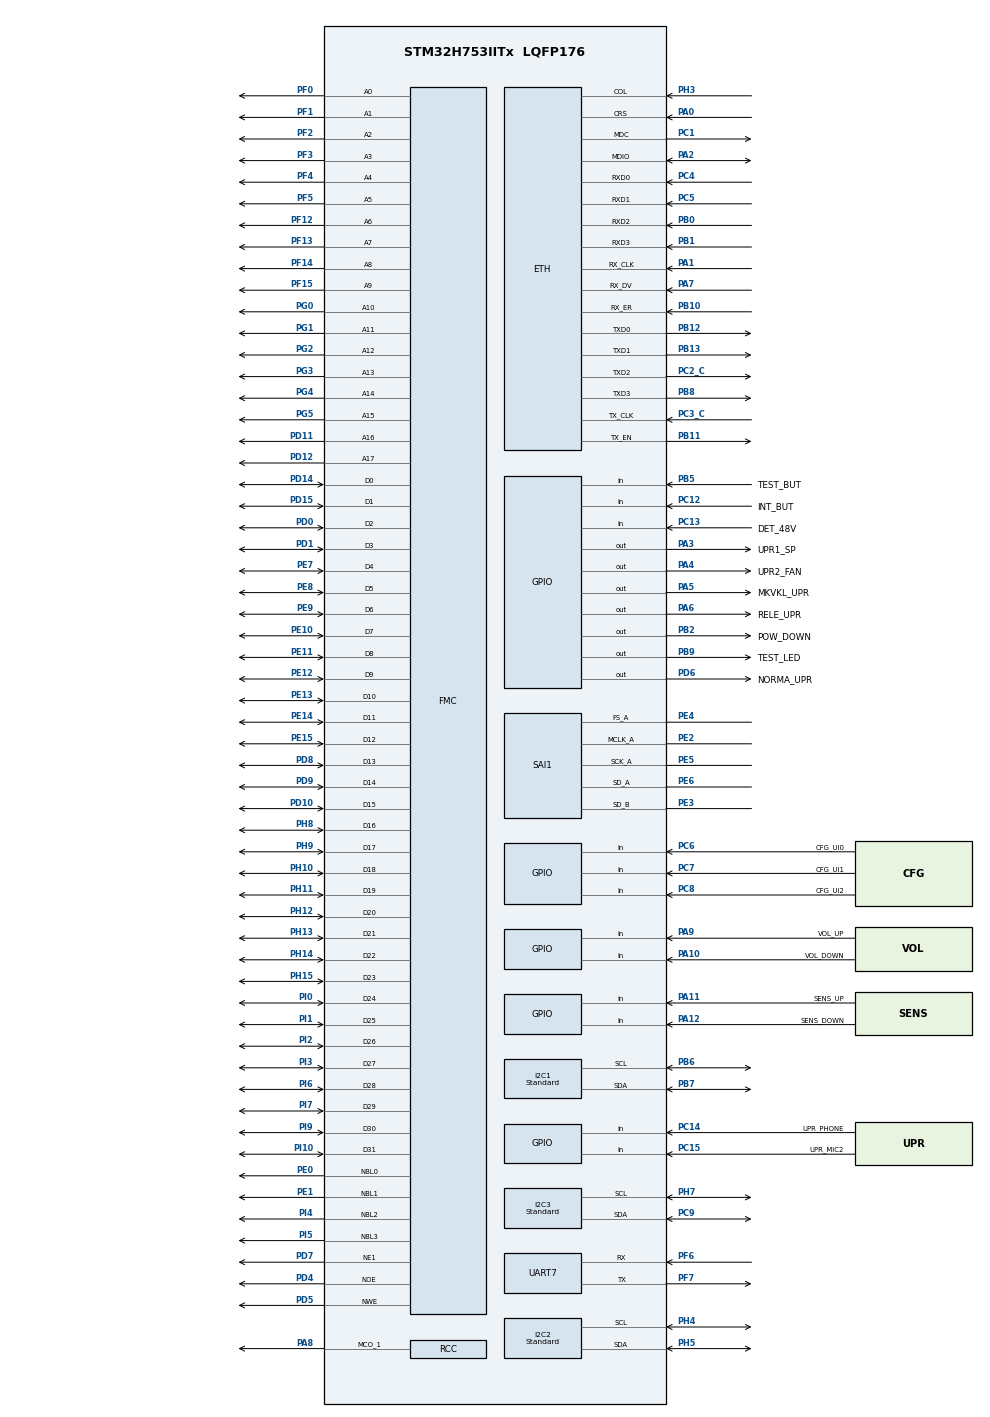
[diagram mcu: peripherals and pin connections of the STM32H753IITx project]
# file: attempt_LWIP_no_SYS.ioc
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CORTEX_M7.AccessPermission-Cortex_Memory_Protection_Unit_Region0_Settings=MPU_REGION_FULL_ACCESS
CORTEX_M7.AccessPermission-Cortex_Memory_Protection_Unit_Region1_Settings=MPU_REGION_FULL_ACCESS
CORTEX_M7.BaseAddress-Cortex_Memory_Protection_Unit_Region0_Settings=0x30000000
CORTEX_M7.BaseAddress-Cortex_Memory_Protection_Unit_Region1_Settings=0x30040000
CORTEX_M7.CPU_DCache=Disabled
CORTEX_M7.CPU_ICache=Disabled
CORTEX_M7.DisableExec-Cortex_Memory_Protection_Unit_Region0_Settings=MPU_INSTRUCTION_ACCESS_ENABLE
CORTEX_M7.Enable-Cortex_Memory_Protection_Unit_Region0_Settings=MPU_REGION_ENABLE
CORTEX_M7.Enable-Cortex_Memory_Protection_Unit_Region1_Settings=MPU_REGION_ENABLE
CORTEX_M7.IsBufferable-Cortex_Memory_Protection_Unit_Region0_Settings=MPU_ACCESS_NOT_BUFFERABLE
CORTEX_M7.IsShareable-Cortex_Memory_Protection_Unit_Region0_Settings=MPU_ACCESS_SHAREABLE
CORTEX_M7.IsShareable-Cortex_Memory_Protection_Unit_Region1_Settings=MPU_ACCESS_SHAREABLE
CORTEX_M7.MPU_Control=__NULL
CORTEX_M7.Size-Cortex_Memory_Protection_Unit_Region0_Settings=MPU_REGION_SIZE_512B
CORTEX_M7.Size-Cortex_Memory_Protection_Unit_Region1_Settings=MPU_REGION_SIZE_32KB
CORTEX_M7.TypeExtField-Cortex_Memory_Protection_Unit_Region0_Settings=MPU_TEX_LEVEL1
CORTEX_M7.TypeExtField-Cortex_Memory_Protection_Unit_Region1_Settings=MPU_TEX_LEVEL0
Dma.Request0=SAI1_A
Dma.Request1=SAI1_B
Dma.SAI1_A.0.Direction=DMA_MEMORY_TO_PERIPH
Dma.SAI1_A.0.EventEnable=DISABLE
Dma.SAI1_A.0.FIFOMode=DMA_FIFOMODE_ENABLE
Dma.SAI1_A.0.FIFOThreshold=DMA_FIFO_THRESHOLD_FULL
Dma.SAI1_A.0.Instance=DMA1_Stream0
Dma.SAI1_A.0.MemBurst=DMA_MBURST_INC8
Dma.SAI1_A.0.MemDataAlignment=DMA_MDATAALIGN_HALFWORD
Dma.SAI1_A.0.MemInc=DMA_MINC_ENABLE
Dma.SAI1_A.0.Mode=DMA_CIRCULAR
Dma.SAI1_A.0.PeriphBurst=DMA_PBURST_SINGLE
Dma.SAI1_A.0.PeriphDataAlignment=DMA_PDATAALIGN_HALFWORD
Dma.SAI1_A.0.PeriphInc=DMA_PINC_DISABLE
Dma.SAI1_A.0.Polarity=HAL_DMAMUX_REQ_GEN_RISING
Dma.SAI1_A.0.Priority=DMA_PRIORITY_VERY_HIGH
Dma.SAI1_A.0.RequestNumber=1
Dma.SAI1_A.0.SignalID=NONE
Dma.SAI1_A.0.SyncEnable=DISABLE
Dma.SAI1_A.0.SyncPolarity=HAL_DMAMUX_SYNC_NO_EVENT
Dma.SAI1_A.0.SyncRequestNumber=1
Dma.SAI1_A.0.SyncSignalID=NONE
Dma.SAI1_B.1.Direction=DMA_PERIPH_TO_MEMORY
Dma.SAI1_B.1.EventEnable=DISABLE
Dma.SAI1_B.1.FIFOMode=DMA_FIFOMODE_ENABLE
Dma.SAI1_B.1.FIFOThreshold=DMA_FIFO_THRESHOLD_FULL
Dma.SAI1_B.1.Instance=DMA1_Stream1
Dma.SAI1_B.1.MemBurst=DMA_MBURST_INC8
Dma.SAI1_B.1.MemDataAlignment=DMA_MDATAALIGN_HALFWORD
Dma.SAI1_B.1.MemInc=DMA_MINC_ENABLE
Dma.SAI1_B.1.Mode=DMA_CIRCULAR
Dma.SAI1_B.1.PeriphBurst=DMA_PBURST_SINGLE
Dma.SAI1_B.1.PeriphDataAlignment=DMA_PDATAALIGN_HALFWORD
Dma.SAI1_B.1.PeriphInc=DMA_PINC_DISABLE
Dma.SAI1_B.1.Polarity=HAL_DMAMUX_REQ_GEN_RISING
Dma.SAI1_B.1.Priority=DMA_PRIORITY_VERY_HIGH
Dma.SAI1_B.1.RequestNumber=1
Dma.SAI1_B.1.SignalID=NONE
Dma.SAI1_B.1.SyncEnable=DISABLE
Dma.SAI1_B.1.SyncPolarity=HAL_DMAMUX_SYNC_NO_EVENT
Dma.SAI1_B.1.SyncRequestNumber=1
Dma.SAI1_B.1.SyncSignalID=NONE
ETH.MACAddr=30\:31\:32\:00\:00\:00
ETH.MediaInterface=HAL_ETH_MII_MODE
ETH.RxBuffAddress=0x30000100
ETH.RxBuffLen=1524
ETH.RxDescAddress=0x30000000
ETH.TxDescAddress=0x30000080
FMC.WriteOperation1=FMC_WRITE_OPERATION_ENABLE
I2C1.I2C_Speed_Mode=I2C_Standard
I2C1.Timing=0x307075B1
I2C2.I2C_Speed_Mode=I2C_Standard
I2C2.Timing=0x307075B1
I2C3.CustomTiming=Disabled
I2C3.I2C_Fall_Time=0
I2C3.I2C_Rise_Time=0
I2C3.I2C_Speed_Mode=I2C_Standard
I2C3.Speed=100
I2C3.Timing=0x307075B1
Mcu.Family=STM32H7
Mcu.Name=STM32H753IITx
Mcu.Package=LQFP176
NVIC.DMA1_Stream0_IRQn=true\:0\:0\:false\:false\:true\:false\:true
NVIC.DMA1_Stream1_IRQn=true\:0\:0\:false\:false\:true\:false\:true
NVIC.ETH_IRQn=true\:1\:0\:true\:false\:true\:true\:true
NVIC.ETH_WKUP_IRQn=true\:1\:0\:true\:false\:true\:true\:true
NVIC.I2C3_EV_IRQn=true\:1\:0\:true\:false\:true\:true\:true
NVIC.PriorityGroup=NVIC_PRIORITYGROUP_4
NVIC.SAI1_IRQn=true\:2\:0\:true\:false\:true\:true\:true
NVIC.TIM3_IRQn=true\:5\:0\:true\:false\:true\:true\:true
NVIC.UART7_IRQn=true\:8\:0\:true\:false\:true\:true\:true
PA0.Mode=MII
PA0.PinAttribute=Free
PA0.Signal=ETH_CRS
PA1.Mode=MII
PA1.PinAttribute=Free
PA1.Signal=ETH_RX_CLK
PA10.GPIO_Label=VOL_DOWN
PA10.GPIO_PuPd=GPIO_PULLUP
PA10.PinAttribute=Free
PA10.Signal=GPIO_Input
PA11.GPIO_Label=SENS_UP
PA11.GPIO_PuPd=GPIO_PULLUP
PA11.PinAttribute=Free
PA11.Signal=GPIO_Input
PA12.GPIO_Label=SENS_DOWN
PA12.GPIO_PuPd=GPIO_PULLUP
PA12.PinAttribute=Free
PA12.Signal=GPIO_Input
PA13\ (JTMS/SWDIO).Mode=JTAG_5_pins
PA13\ (JTMS/SWDIO).PinAttribute=Free
PA13\ (JTMS/SWDIO).Signal=DEBUG_JTMS-SWDIO
PA14\ (JTCK/SWCLK).Mode=JTAG_5_pins
PA14\ (JTCK/SWCLK).PinAttribute=Free
PA14\ (JTCK/SWCLK).Signal=DEBUG_JTCK-SWCLK
PA15\ (JTDI).Mode=JTAG_5_pins
PA15\ (JTDI).PinAttribute=Free
PA15\ (JTDI).Signal=DEBUG_JTDI
PA2.Mode=MII
PA2.PinAttribute=Free
PA2.Signal=ETH_MDIO
PA3.GPIO_Label=UPR1_SP
PA3.GPIO_PuPd=GPIO_PULLUP
PA3.PinAttribute=Free
PA3.PinState=GPIO_PIN_RESET
PA3.Signal=GPIO_Output
PA4.GPIO_Label=UPR2_FAN
PA4.GPIO_PuPd=GPIO_PULLUP
PA4.PinAttribute=Free
PA4.PinState=GPIO_PIN_SET
PA4.Signal=GPIO_Output
PA5.GPIO_Label=MKVKL_UPR
PA5.GPIO_PuPd=GPIO_PULLUP
PA5.PinAttribute=Free
PA5.Signal=GPIO_Output
PA6.GPIO_Label=RELE_UPR
PA6.GPIO_PuPd=GPIO_PULLUP
PA6.PinAttribute=Free
PA6.PinState=GPIO_PIN_SET
PA6.Signal=GPIO_Output
PA7.Mode=MII
PA7.PinAttribute=Free
PA7.Signal=ETH_RX_DV
PA8.GPIO_PuPd=GPIO_PULLUP
PA8.Mode=Clock-out-1
PA8.PinAttribute=Free
PA8.Signal=RCC_MCO_1
PA9.GPIO_Label=VOL_UP
PA9.GPIO_PuPd=GPIO_PULLUP
PA9.PinAttribute=Free
PA9.Signal=GPIO_Input
PB0.Mode=MII
PB0.PinAttribute=Free
PB0.Signal=ETH_RXD2
PB1.Mode=MII
PB1.PinAttribute=Free
PB1.Signal=ETH_RXD3
PB10.Mode=Activate Rx Err signal
PB10.Signal=ETH_RX_ER
PB11.Mode=MII
PB11.PinAttribute=Free
PB11.Signal=ETH_TX_EN
PB12.Mode=MII
PB12.PinAttribute=Free
PB12.Signal=ETH_TXD0
PB13.Mode=MII
PB13.PinAttribute=Free
PB13.Signal=ETH_TXD1
PB2.GPIO_Label=POW_DOWN
PB2.GPIO_PuPd=GPIO_PULLUP
PB2.PinAttribute=Free
PB2.PinState=GPIO_PIN_SET
PB2.Signal=GPIO_Output
PB3\ (JTDO/TRACESWO).Mode=JTAG_5_pins
PB3\ (JTDO/TRACESWO).Signal=DEBUG_JTDO-SWO
PB4\ (NJTRST).Mode=JTAG_5_pins
PB4\ (NJTRST).Signal=DEBUG_JTRST
PB5.GPIO_Label=TEST_BUT
PB5.GPIO_PuPd=GPIO_PULLUP
PB5.Signal=GPIO_Input
PB6.GPIO_Pu=GPIO_PULLUP
PB6.GPIO_PuPd=GPIO_PULLUP
PB6.GPIO_Speed=GPIO_SPEED_FREQ_HIGH
PB6.Mode=I2C
PB6.PinAttribute=Free
PB6.Signal=I2C1_SCL
PB7.GPIO_Pu=GPIO_PULLUP
PB7.GPIO_PuPd=GPIO_PULLUP
PB7.GPIO_Speed=GPIO_SPEED_FREQ_HIGH
PB7.Mode=I2C
PB7.PinAttribute=Free
PB7.Signal=I2C1_SDA
PB8.GPIO_FM8=__NULL
PB8.Mode=MII
PB8.PinAttribute=Free
PB8.Signal=ETH_TXD3
PB9.GPIO_Label=TEST_LED
PB9.GPIO_ModeDefaultOutputPP=GPIO_MODE_OUTPUT_PP
PB9.GPIO_PuPd=GPIO_PULLUP
PB9.Signal=GPIO_Output
PC1.Mode=MII
PC1.PinAttribute=Free
PC1.Signal=ETH_MDC
PC12.GPIO_Label=INT_BUT
PC12.GPIO_PuPd=GPIO_PULLUP
PC12.PinAttribute=Free
PC12.Signal=GPIO_Input
PC13.GPIO_Label=DET_48V
PC13.GPIO_PuPd=GPIO_PULLUP
PC13.PinAttribute=Free
PC13.Signal=GPIO_Input
PC14-OSC32_IN\ (OSC32_IN).GPIO_Label=UPR_PHONE
PC14-OSC32_IN\ (OSC32_IN).GPIO_PuPd=GPIO_PULLUP
PC14-OSC32_IN\ (OSC32_IN).PinAttribute=Free
PC14-OSC32_IN\ (OSC32_IN).Signal=GPIO_Input
PC15-OSC32_OUT\ (OSC32_OUT).GPIO_Label=UPR_MIC2
PC15-OSC32_OUT\ (OSC32_OUT).GPIO_PuPd=GPIO_PULLUP
PC15-OSC32_OUT\ (OSC32_OUT).PinAttribute=Free
PC15-OSC32_OUT\ (OSC32_OUT).Signal=GPIO_Input
PC2_C.Mode=MII
PC2_C.PinAttribute=Free
PC2_C.Signal=ETH_TXD2
PC3_C.Mode=MII
PC3_C.PinAttribute=Free
PC3_C.Signal=ETH_TX_CLK
PC4.Mode=MII
PC4.PinAttribute=Free
PC4.Signal=ETH_RXD0
PC5.Mode=MII
PC5.PinAttribute=Free
PC5.Signal=ETH_RXD1
PC6.GPIO_Label=CFG_UI0
PC6.GPIO_PuPd=GPIO_PULLUP
PC6.PinAttribute=Free
PC6.Signal=GPIO_Input
PC7.GPIO_Label=CFG_UI1
PC7.GPIO_PuPd=GPIO_PULLUP
PC7.PinAttribute=Free
PC7.Signal=GPIO_Input
PC8.GPIO_Label=CFG_UI2
PC8.GPIO_PuPd=GPIO_PULLUP
PC8.PinAttribute=Free
PC8.Signal=GPIO_Input
PC9.GPIO_Mode=GPIO_MODE_AF_OD
PC9.GPIO_Pu=GPIO_PULLUP
PC9.GPIO_PuPd=GPIO_NOPULL
PC9.GPIO_Speed=GPIO_SPEED_FREQ_VERY_HIGH
PC9.Mode=I2C
PC9.PinAttribute=Free
PC9.Signal=I2C3_SDA
PD0.PinAttribute=Free
PD0.Signal=FMC_D2_DA2
PD1.PinAttribute=Free
PD1.Signal=FMC_D3_DA3
PD10.PinAttribute=Free
PD10.Signal=FMC_D15_DA15
PD11.PinAttribute=Free
PD11.Signal=FMC_A16_CLE
PD12.PinAttribute=Free
PD12.Signal=FMC_A17_ALE
PD14.PinAttribute=Free
PD14.Signal=FMC_D0_DA0
PD15.PinAttribute=Free
PD15.Signal=FMC_D1_DA1
PD4.PinAttribute=Free
PD4.Signal=FMC_NOE
PD5.PinAttribute=Free
PD5.Signal=FMC_NWE
PD6.GPIO_Label=NORMA_UPR
PD6.GPIO_PuPd=GPIO_PULLUP
PD6.PinAttribute=Free
PD6.Signal=GPIO_Output
PD7.Mode=NorPsramChipSelect1_1
PD7.Signal=FMC_NE1
PD8.PinAttribute=Free
PD8.Signal=FMC_D13_DA13
PD9.PinAttribute=Free
PD9.Signal=FMC_D14_DA14
PE0.Signal=FMC_NBL0
PE1.Signal=FMC_NBL1
PE10.PinAttribute=Free
PE10.Signal=FMC_D7_DA7
PE11.PinAttribute=Free
PE11.Signal=FMC_D8_DA8
PE12.PinAttribute=Free
PE12.Signal=FMC_D9_DA9
PE13.PinAttribute=Free
PE13.Signal=FMC_D10_DA10
PE14.PinAttribute=Free
PE14.Signal=FMC_D11_DA11
PE15.PinAttribute=Free
PE15.Signal=FMC_D12_DA12
PE2.GPIO_Speed=GPIO_SPEED_FREQ_VERY_HIGH
PE2.Mode=SAI_A_MasterWithClock
PE2.PinAttribute=Free
PE2.Signal=SAI1_MCLK_A
PE3.GPIO_Speed=GPIO_SPEED_FREQ_VERY_HIGH
PE3.Mode=SAI_B_SyncSlave
PE3.PinAttribute=Free
PE3.Signal=SAI1_SD_B
PE4.GPIO_Speed=GPIO_SPEED_FREQ_VERY_HIGH
PE4.Mode=SAI_A_MasterWithClock
PE4.PinAttribute=Free
PE4.Signal=SAI1_FS_A
PE5.GPIO_Speed=GPIO_SPEED_FREQ_VERY_HIGH
PE5.Mode=SAI_A_MasterWithClock
PE5.PinAttribute=Free
PE5.Signal=SAI1_SCK_A
PE6.GPIO_Speed=GPIO_SPEED_FREQ_VERY_HIGH
PE6.Mode=SAI_A_MasterWithClock
PE6.PinAttribute=Free
PE6.Signal=SAI1_SD_A
PE7.PinAttribute=Free
PE7.Signal=FMC_D4_DA4
PE8.PinAttribute=Free
PE8.Signal=FMC_D5_DA5
PE9.PinAttribute=Free
PE9.Signal=FMC_D6_DA6
PF0.PinAttribute=Free
PF0.Signal=FMC_A0
PF1.PinAttribute=Free
PF1.Signal=FMC_A1
PF12.PinAttribute=Free
PF12.Signal=FMC_A6
PF13.PinAttribute=Free
PF13.Signal=FMC_A7
PF14.PinAttribute=Free
PF14.Signal=FMC_A8
PF15.PinAttribute=Free
PF15.Signal=FMC_A9
PF2.PinAttribute=Free
PF2.Signal=FMC_A2
PF3.PinAttribute=Free
PF3.Signal=FMC_A3
PF4.PinAttribute=Free
PF4.Signal=FMC_A4
PF5.PinAttribute=Free
PF5.Signal=FMC_A5
PF6.GPIO_PuPd=GPIO_PULLUP
PF6.Mode=Asynchronous
PF6.PinAttribute=Free
PF6.Signal=UART7_RX
PF7.GPIO_PuPd=GPIO_PULLUP
PF7.Mode=Asynchronous
PF7.PinAttribute=Free
PF7.Signal=UART7_TX
PG0.PinAttribute=Free
PG0.Signal=FMC_A10
PG1.PinAttribute=Free
PG1.Signal=FMC_A11
PG2.PinAttribute=Free
PG2.Signal=FMC_A12
PG3.PinAttribute=Free
PG3.Signal=FMC_A13
PG4.PinAttribute=Free
PG4.Signal=FMC_A14_BA0
PG5.PinAttribute=Free
PG5.Signal=FMC_A15_BA1
PH0-OSC_IN\ (PH0).Mode=HSE-External-Oscillator
PH0-OSC_IN\ (PH0).PinAttribute=Free
PH0-OSC_IN\ (PH0).Signal=RCC_OSC_IN
PH1-OSC_OUT\ (PH1).Mode=HSE-External-Oscillator
PH1-OSC_OUT\ (PH1).PinAttribute=Free
PH1-OSC_OUT\ (PH1).Signal=RCC_OSC_OUT
PH10.PinAttribute=Free
PH10.Signal=FMC_D18
PH11.PinAttribute=Free
PH11.Signal=FMC_D19
PH12.PinAttribute=Free
PH12.Signal=FMC_D20
PH13.PinAttribute=Free
PH13.Signal=FMC_D21
PH14.PinAttribute=Free
PH14.Signal=FMC_D22
PH15.PinAttribute=Free
PH15.Signal=FMC_D23
PH3.Mode=MII
PH3.PinAttribute=Free
PH3.Signal=ETH_COL
PH4.GPIO_Pu=GPIO_PULLUP
PH4.GPIO_PuPd=GPIO_PULLUP
PH4.GPIO_Speed=GPIO_SPEED_FREQ_HIGH
PH4.Mode=I2C
PH4.PinAttribute=Free
PH4.Signal=I2C2_SCL
PH5.GPIO_Pu=GPIO_PULLUP
PH5.GPIO_PuPd=GPIO_PULLUP
PH5.GPIO_Speed=GPIO_SPEED_FREQ_HIGH
PH5.Mode=I2C
PH5.PinAttribute=Free
PH5.Signal=I2C2_SDA
PH7.GPIO_Pu=GPIO_PULLUP
PH7.GPIO_PuPd=GPIO_NOPULL
PH7.GPIO_Speed=GPIO_SPEED_FREQ_VERY_HIGH
PH7.Mode=I2C
PH7.PinAttribute=Free
PH7.Signal=I2C3_SCL
PH8.PinAttribute=Free
PH8.Signal=FMC_D16
PH9.PinAttribute=Free
PH9.Signal=FMC_D17
PI0.PinAttribute=Free
PI0.Signal=FMC_D24
PI1.PinAttribute=Free
PI1.Signal=FMC_D25
PI10.PinAttribute=Free
PI10.Signal=FMC_D31
PI2.PinAttribute=Free
PI2.Signal=FMC_D26
PI3.PinAttribute=Free
PI3.Signal=FMC_D27
PI4.Signal=FMC_NBL2
PI5.Signal=FMC_NBL3
PI6.Signal=FMC_D28
PI7.Signal=FMC_D29
PI9.PinAttribute=Free
PI9.Signal=FMC_D30
ProjectManager.HeapSize=0x200
ProjectManager.StackSize=0x400
ProjectManager.TargetToolchain=STM32CubeIDE
RCC.ADCFreq_Value=4096000
RCC.APB1Freq_Value=120000000
RCC.APB2Freq_Value=120000000
RCC.APB3Freq_Value=120000000
RCC.APB4Freq_Value=120000000
RCC.CKPERSourceSelection=RCC_CLKPSOURCE_HSE
RCC.CortexFreq_Value=480000000
RCC.D1PPRE=RCC_APB3_DIV2
RCC.D2PPRE1=RCC_APB1_DIV2
RCC.D2PPRE2=RCC_APB2_DIV2
RCC.D3PPRE=RCC_APB4_DIV2
RCC.DIVM1=10
RCC.DIVM2=25
RCC.DIVM3=25
RCC.DIVN1=384
RCC.DIVN2=512
RCC.DIVN3=150
RCC.DIVP2=125
RCC.DIVP3=1
RCC.DIVQ1=10
RCC.DIVQ2=125
RCC.DIVQ3=1
RCC.DIVR1=4
RCC.DIVR2=125
RCC.DIVR3=1
RCC.EnbaleCSS=true
RCC.FMCCLockSelection=RCC_FMCCLKSOURCE_PLL
RCC.HCLKFreq_Value=240000000
RCC.HPRE=RCC_HCLK_DIV2
RCC.HSIDiv=RCC_PLLSAIDIVR_8
RCC.PLL2FRACN=0
RCC.PLL3FRACN=0
RCC.PLLFRACN=0
RCC.PLLSourceVirtual=RCC_PLLSOURCE_HSE
RCC.RCC_MCO1Source=RCC_MCO1SOURCE_HSE
RCC.SAI1CLockSelection=RCC_SAI1CLKSOURCE_PLL2
RCC.SYSCLKFreq_VALUE=480000000
RCC.SYSCLKSource=RCC_SYSCLKSOURCE_PLLCLK
RCC.USBFreq_Value=96000000
SAI1.AudioFrequency-SAI_A_MasterWithClock=SAI_AUDIO_FREQUENCY_8K
SAI1.ErrorAudioFreq-SAI_A_MasterWithClock=0.0 %
SAI1.InitProtocol-SAI_A_MasterWithClock=Enable
SAI1.InitProtocol-SAI_B_SyncSlave=Enable
SAI1.Instance-SAI_A_MasterWithClock=SAI$Index_Block_A
SAI1.Instance-SAI_B_SyncSlave=SAI$Index_Block_B
SAI1.MClockEnable-SAI_A_MasterWithClock=SAI_MASTERCLOCK_ENABLE
SAI1.MonoStereoMode-SAI_A_MasterWithClock=SAI_STEREOMODE
SAI1.MonoStereoMode-SAI_B_SyncSlave=SAI_STEREOMODE
SAI1.RealAudioFreq-SAI_A_MasterWithClock=8.0 KHz
SAI1.VirtualMode-SAI_A_MasterWithClock=VM_MASTER
SAI1.VirtualMode-SAI_B_SyncSlave=VM_SLAVE
SAI1.VirtualProtocol-SAI_A_BASIC=VM_BASIC_PROTOCOL
SAI1.VirtualProtocol-SAI_B_BASIC=VM_BASIC_PROTOCOL
SH.FMC_A0.0=FMC_A0,18b-a1
SH.FMC_A1.0=FMC_A1,18b-a1
SH.FMC_A10.0=FMC_A10,18b-a1
SH.FMC_A11.0=FMC_A11,18b-a1
SH.FMC_A12.0=FMC_A12,18b-a1
SH.FMC_A13.0=FMC_A13,18b-a1
SH.FMC_A14_BA0.0=FMC_A14,18b-a1
SH.FMC_A15_BA1.0=FMC_A15,18b-a1
SH.FMC_A16_CLE.0=FMC_A16,18b-a1
SH.FMC_A17_ALE.0=FMC_A17,18b-a1
SH.FMC_A2.0=FMC_A2,18b-a1
SH.FMC_A3.0=FMC_A3,18b-a1
SH.FMC_A4.0=FMC_A4,18b-a1
SH.FMC_A5.0=FMC_A5,18b-a1
SH.FMC_A6.0=FMC_A6,18b-a1
SH.FMC_A7.0=FMC_A7,18b-a1
SH.FMC_A8.0=FMC_A8,18b-a1
SH.FMC_A9.0=FMC_A9,18b-a1
SH.FMC_D0_DA0.0=FMC_D0,32b-d1
SH.FMC_D10_DA10.0=FMC_D10,32b-d1
SH.FMC_D11_DA11.0=FMC_D11,32b-d1
SH.FMC_D12_DA12.0=FMC_D12,32b-d1
SH.FMC_D13_DA13.0=FMC_D13,32b-d1
SH.FMC_D14_DA14.0=FMC_D14,32b-d1
SH.FMC_D15_DA15.0=FMC_D15,32b-d1
SH.FMC_D16.0=FMC_D16,32b-d1
SH.FMC_D17.0=FMC_D17,32b-d1
SH.FMC_D18.0=FMC_D18,32b-d1
SH.FMC_D19.0=FMC_D19,32b-d1
SH.FMC_D1_DA1.0=FMC_D1,32b-d1
SH.FMC_D20.0=FMC_D20,32b-d1
SH.FMC_D21.0=FMC_D21,32b-d1
SH.FMC_D22.0=FMC_D22,32b-d1
SH.FMC_D23.0=FMC_D23,32b-d1
SH.FMC_D24.0=FMC_D24,32b-d1
SH.FMC_D25.0=FMC_D25,32b-d1
SH.FMC_D26.0=FMC_D26,32b-d1
SH.FMC_D27.0=FMC_D27,32b-d1
SH.FMC_D28.0=FMC_D28,32b-d1
SH.FMC_D29.0=FMC_D29,32b-d1
SH.FMC_D2_DA2.0=FMC_D2,32b-d1
SH.FMC_D30.0=FMC_D30,32b-d1
SH.FMC_D31.0=FMC_D31,32b-d1
SH.FMC_D3_DA3.0=FMC_D3,32b-d1
SH.FMC_D4_DA4.0=FMC_D4,32b-d1
SH.FMC_D5_DA5.0=FMC_D5,32b-d1
SH.FMC_D6_DA6.0=FMC_D6,32b-d1
SH.FMC_D7_DA7.0=FMC_D7,32b-d1
SH.FMC_D8_DA8.0=FMC_D8,32b-d1
SH.FMC_D9_DA9.0=FMC_D9,32b-d1
SH.FMC_NBL0.0=FMC_NBL0,4ByteEnable1
SH.FMC_NBL1.0=FMC_NBL1,4ByteEnable1
SH.FMC_NBL2.0=FMC_NBL2,4ByteEnable1
SH.FMC_NBL3.0=FMC_NBL3,4ByteEnable1
SH.FMC_NOE.0=FMC_NOE,Sram1
SH.FMC_NWE.0=FMC_NWE,Sram1
TIM3.Period=15000
UART7.FIFOMode=FIFOMODE_ENABLE
UART7.RXFIFOThreshold=RXFIFO_THRESHOLD_HALFFULL
UART7.TXFIFOThreshold=TXFIFO_THRESHOLD_HALFFULL
VP_SAI1_VP_$IpInstance_SAIA_SAI_BASIC.Mode=SAI_A_BASIC
VP_SAI1_VP_$IpInstance_SAIB_SAI_BASIC.Mode=SAI_B_BASIC
VP_TIM3_VS_ClockSourceINT.Mode=Internal
board=custom

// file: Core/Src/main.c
/* USER CODE BEGIN Header */
/**
  ******************************************************************************
  * @file           : main.c
  * @brief          : Main program body
  ******************************************************************************
  * @attention
  *
  * Copyright (c) 2022 STMicroelectronics.
  * All rights reserved.
  *
  * This software is licensed under terms that can be found in the LICENSE file
  * in the root directory of this software component.
  * If no LICENSE file comes with this software, it is provided AS-IS.
  *
  ******************************************************************************
  */
/* USER CODE END Header */
#include "main.h"
#include "string.h"

#if defined ( __ICCARM__ ) /*!< IAR Compiler */

#pragma location=0x30000000
ETH_DMADescTypeDef  DMARxDscrTab[ETH_RX_DESC_CNT]; /* Ethernet Rx DMA Descriptors */
#pragma location=0x30000080
ETH_DMADescTypeDef  DMATxDscrTab[ETH_TX_DESC_CNT]; /* Ethernet Tx DMA Descriptors */
#pragma location=0x30000100
uint8_t Rx_Buff[ETH_RX_DESC_CNT][ETH_MAX_PACKET_SIZE]; /* Ethernet Receive Buffers */

#elif defined ( __CC_ARM )  /* MDK ARM Compiler */

__attribute__((at(0x30000000))) ETH_DMADescTypeDef  DMARxDscrTab[ETH_RX_DESC_CNT]; /* Ethernet Rx DMA Descriptors */
__attribute__((at(0x30000080))) ETH_DMADescTypeDef  DMATxDscrTab[ETH_TX_DESC_CNT]; /* Ethernet Tx DMA Descriptors */
__attribute__((at(0x30000100))) uint8_t Rx_Buff[ETH_RX_DESC_CNT][ETH_MAX_PACKET_SIZE]; /* Ethernet Receive Buffer */

#elif defined ( __GNUC__ ) /* GNU Compiler */

ETH_DMADescTypeDef DMARxDscrTab[ETH_RX_DESC_CNT] __attribute__((section(".RxDecripSection"))); /* Ethernet Rx DMA Descriptors */
ETH_DMADescTypeDef DMATxDscrTab[ETH_TX_DESC_CNT] __attribute__((section(".TxDecripSection")));   /* Ethernet Tx DMA Descriptors */
uint8_t Rx_Buff[ETH_RX_DESC_CNT][ETH_MAX_PACKET_SIZE] __attribute__((section(".RxArraySection"))); /* Ethernet Receive Buffers */

#endif

ETH_TxPacketConfig TxConfig;

ETH_HandleTypeDef heth;

I2C_HandleTypeDef hi2c1;
I2C_HandleTypeDef hi2c2;
I2C_HandleTypeDef hi2c3;

SAI_HandleTypeDef hsai_BlockA1;
SAI_HandleTypeDef hsai_BlockB1;
DMA_HandleTypeDef hdma_sai1_a;
DMA_HandleTypeDef hdma_sai1_b;

TIM_HandleTypeDef htim3;

UART_HandleTypeDef huart7;

SRAM_HandleTypeDef hsram1;

void SystemClock_Config(void);
void PeriphCommonClock_Config(void);
static void MX_GPIO_Init(void);
static void MX_DMA_Init(void);
static void MX_FMC_Init(void);
static void MX_I2C1_Init(void);
static void MX_I2C2_Init(void);
static void MX_I2C3_Init(void);
static void MX_SAI1_Init(void);
static void MX_UART7_Init(void);
static void MX_TIM3_Init(void);
static void MX_ETH_Init(void);
/* USER CODE BEGIN PFP */
extern struct netif gnetif;
/* USER CODE END PFP */

int main(void)
{

  /* MCU Configuration--------------------------------------------------------*/

  /* Reset of all peripherals, Initializes the Flash interface and the Systick. */
  HAL_Init();

  /* Configure the system clock */
  SystemClock_Config();

/* Configure the peripherals common clocks */
  PeriphCommonClock_Config();

  /* Initialize all configured peripherals */
  MX_GPIO_Init();
  MX_DMA_Init();
  MX_FMC_Init();
  MX_I2C1_Init();
  MX_I2C2_Init();
  MX_I2C3_Init();
  MX_SAI1_Init();
  MX_UART7_Init();
  MX_TIM3_Init();
  MX_ETH_Init();

  /* Infinite loop */
  while (1)
  {

  }
}

void SystemClock_Config(void)
{
  RCC_OscInitTypeDef RCC_OscInitStruct = {0};
  RCC_ClkInitTypeDef RCC_ClkInitStruct = {0};

  /** Supply configuration update enable
  */
  HAL_PWREx_ConfigSupply(PWR_LDO_SUPPLY);
  /** Configure the main internal regulator output voltage
  */
  __HAL_PWR_VOLTAGESCALING_CONFIG(PWR_REGULATOR_VOLTAGE_SCALE0);

  while(!__HAL_PWR_GET_FLAG(PWR_FLAG_VOSRDY)) {}
  /** Macro to configure the PLL clock source
  */
  __HAL_RCC_PLL_PLLSOURCE_CONFIG(RCC_PLLSOURCE_HSE);
  /** Initializes the RCC Oscillators according to the specified parameters
  * in the RCC_OscInitTypeDef structure.
  */
  RCC_OscInitStruct.OscillatorType = RCC_OSCILLATORTYPE_HSE;
  RCC_OscInitStruct.HSEState = RCC_HSE_ON;
  RCC_OscInitStruct.PLL.PLLState = RCC_PLL_ON;
  RCC_OscInitStruct.PLL.PLLSource = RCC_PLLSOURCE_HSE;
  RCC_OscInitStruct.PLL.PLLM = 10;
  RCC_OscInitStruct.PLL.PLLN = 384;
  RCC_OscInitStruct.PLL.PLLP = 2;
  RCC_OscInitStruct.PLL.PLLQ = 10;
  RCC_OscInitStruct.PLL.PLLR = 4;
  RCC_OscInitStruct.PLL.PLLRGE = RCC_PLL1VCIRANGE_1;
  RCC_OscInitStruct.PLL.PLLVCOSEL = RCC_PLL1VCOWIDE;
  RCC_OscInitStruct.PLL.PLLFRACN = 0;
  if (HAL_RCC_OscConfig(&RCC_OscInitStruct) != HAL_OK)
  {
    Error_Handler();
  }
  /** Initializes the CPU, AHB and APB buses clocks
  */
  RCC_ClkInitStruct.ClockType = RCC_CLOCKTYPE_HCLK|RCC_CLOCKTYPE_SYSCLK
                              |RCC_CLOCKTYPE_PCLK1|RCC_CLOCKTYPE_PCLK2
                              |RCC_CLOCKTYPE_D3PCLK1|RCC_CLOCKTYPE_D1PCLK1;
  RCC_ClkInitStruct.SYSCLKSource = RCC_SYSCLKSOURCE_PLLCLK;
  RCC_ClkInitStruct.SYSCLKDivider = RCC_SYSCLK_DIV1;
  RCC_ClkInitStruct.AHBCLKDivider = RCC_HCLK_DIV2;
  RCC_ClkInitStruct.APB3CLKDivider = RCC_APB3_DIV2;
  RCC_ClkInitStruct.APB1CLKDivider = RCC_APB1_DIV2;
  RCC_ClkInitStruct.APB2CLKDivider = RCC_APB2_DIV2;
  RCC_ClkInitStruct.APB4CLKDivider = RCC_APB4_DIV2;

  if (HAL_RCC_ClockConfig(&RCC_ClkInitStruct, FLASH_LATENCY_4) != HAL_OK)
  {
    Error_Handler();
  }
  HAL_RCC_MCOConfig(RCC_MCO1, RCC_MCO1SOURCE_HSE, RCC_MCODIV_1);
  /** Enables the Clock Security System
  */
  HAL_RCC_EnableCSS();
}

void PeriphCommonClock_Config(void)
{
  RCC_PeriphCLKInitTypeDef PeriphClkInitStruct = {0};

  /** Initializes the peripherals clock
  */
  PeriphClkInitStruct.PeriphClockSelection = RCC_PERIPHCLK_SAI1;
  PeriphClkInitStruct.PLL2.PLL2M = 25;
  PeriphClkInitStruct.PLL2.PLL2N = 512;
  PeriphClkInitStruct.PLL2.PLL2P = 125;
  PeriphClkInitStruct.PLL2.PLL2Q = 125;
  PeriphClkInitStruct.PLL2.PLL2R = 125;
  PeriphClkInitStruct.PLL2.PLL2RGE = RCC_PLL2VCIRANGE_0;
  PeriphClkInitStruct.PLL2.PLL2VCOSEL = RCC_PLL2VCOWIDE;
  PeriphClkInitStruct.PLL2.PLL2FRACN = 0;
  PeriphClkInitStruct.Sai1ClockSelection = RCC_SAI1CLKSOURCE_PLL2;
  if (HAL_RCCEx_PeriphCLKConfig(&PeriphClkInitStruct) != HAL_OK)
  {
    Error_Handler();
  }
}

static void MX_ETH_Init(void)
{

   static uint8_t MACAddr[6];

  heth.Instance = ETH;
  MACAddr[0] = 0x30;
  MACAddr[1] = 0x31;
  MACAddr[2] = 0x32;
  MACAddr[3] = 0x00;
  MACAddr[4] = 0x00;
  MACAddr[5] = 0x00;
  heth.Init.MACAddr = &MACAddr[0];
  heth.Init.MediaInterface = HAL_ETH_MII_MODE;
  heth.Init.TxDesc = DMATxDscrTab;
  heth.Init.RxDesc = DMARxDscrTab;
  heth.Init.RxBuffLen = 1524;

  if (HAL_ETH_Init(&heth) != HAL_OK)
  {
    Error_Handler();
  }

  memset(&TxConfig, 0 , sizeof(ETH_TxPacketConfig));
  TxConfig.Attributes = ETH_TX_PACKETS_FEATURES_CSUM | ETH_TX_PACKETS_FEATURES_CRCPAD;
  TxConfig.ChecksumCtrl = ETH_CHECKSUM_IPHDR_PAYLOAD_INSERT_PHDR_CALC;
  TxConfig.CRCPadCtrl = ETH_CRC_PAD_INSERT;

}

static void MX_I2C1_Init(void)
{

  hi2c1.Instance = I2C1;
  hi2c1.Init.Timing = 0x307075B1;
  hi2c1.Init.OwnAddress1 = 0;
  hi2c1.Init.AddressingMode = I2C_ADDRESSINGMODE_7BIT;
  hi2c1.Init.DualAddressMode = I2C_DUALADDRESS_DISABLE;
  hi2c1.Init.OwnAddress2 = 0;
  hi2c1.Init.OwnAddress2Masks = I2C_OA2_NOMASK;
  hi2c1.Init.GeneralCallMode = I2C_GENERALCALL_DISABLE;
  hi2c1.Init.NoStretchMode = I2C_NOSTRETCH_DISABLE;
  if (HAL_I2C_Init(&hi2c1) != HAL_OK)
  {
    Error_Handler();
  }
  /** Configure Analogue filter
  */
  if (HAL_I2CEx_ConfigAnalogFilter(&hi2c1, I2C_ANALOGFILTER_ENABLE) != HAL_OK)
  {
    Error_Handler();
  }
  /** Configure Digital filter
  */
  if (HAL_I2CEx_ConfigDigitalFilter(&hi2c1, 0) != HAL_OK)
  {
    Error_Handler();
  }

}

static void MX_I2C2_Init(void)
{

  hi2c2.Instance = I2C2;
  hi2c2.Init.Timing = 0x307075B1;
  hi2c2.Init.OwnAddress1 = 0;
  hi2c2.Init.AddressingMode = I2C_ADDRESSINGMODE_7BIT;
  hi2c2.Init.DualAddressMode = I2C_DUALADDRESS_DISABLE;
  hi2c2.Init.OwnAddress2 = 0;
  hi2c2.Init.OwnAddress2Masks = I2C_OA2_NOMASK;
  hi2c2.Init.GeneralCallMode = I2C_GENERALCALL_DISABLE;
  hi2c2.Init.NoStretchMode = I2C_NOSTRETCH_DISABLE;
  if (HAL_I2C_Init(&hi2c2) != HAL_OK)
  {
    Error_Handler();
  }
  /** Configure Analogue filter
  */
  if (HAL_I2CEx_ConfigAnalogFilter(&hi2c2, I2C_ANALOGFILTER_ENABLE) != HAL_OK)
  {
    Error_Handler();
  }
  /** Configure Digital filter
  */
  if (HAL_I2CEx_ConfigDigitalFilter(&hi2c2, 0) != HAL_OK)
  {
    Error_Handler();
  }

}

static void MX_I2C3_Init(void)
{

  hi2c3.Instance = I2C3;
  hi2c3.Init.Timing = 0x307075B1;
  hi2c3.Init.OwnAddress1 = 0;
  hi2c3.Init.AddressingMode = I2C_ADDRESSINGMODE_7BIT;
  hi2c3.Init.DualAddressMode = I2C_DUALADDRESS_DISABLE;
  hi2c3.Init.OwnAddress2 = 0;
  hi2c3.Init.OwnAddress2Masks = I2C_OA2_NOMASK;
  hi2c3.Init.GeneralCallMode = I2C_GENERALCALL_DISABLE;
  hi2c3.Init.NoStretchMode = I2C_NOSTRETCH_DISABLE;
  if (HAL_I2C_Init(&hi2c3) != HAL_OK)
  {
    Error_Handler();
  }
  /** Configure Analogue filter
  */
  if (HAL_I2CEx_ConfigAnalogFilter(&hi2c3, I2C_ANALOGFILTER_ENABLE) != HAL_OK)
  {
    Error_Handler();
  }
  /** Configure Digital filter
  */
  if (HAL_I2CEx_ConfigDigitalFilter(&hi2c3, 0) != HAL_OK)
  {
    Error_Handler();
  }

}

static void MX_SAI1_Init(void)
{

  hsai_BlockA1.Instance = SAI1_Block_A;
  hsai_BlockA1.Init.AudioMode = SAI_MODEMASTER_TX;
  hsai_BlockA1.Init.Synchro = SAI_ASYNCHRONOUS;
  hsai_BlockA1.Init.OutputDrive = SAI_OUTPUTDRIVE_DISABLE;
  hsai_BlockA1.Init.NoDivider = SAI_MASTERDIVIDER_ENABLE;
  hsai_BlockA1.Init.FIFOThreshold = SAI_FIFOTHRESHOLD_EMPTY;
  hsai_BlockA1.Init.AudioFrequency = SAI_AUDIO_FREQUENCY_8K;
  hsai_BlockA1.Init.SynchroExt = SAI_SYNCEXT_DISABLE;
  hsai_BlockA1.Init.MonoStereoMode = SAI_STEREOMODE;
  hsai_BlockA1.Init.CompandingMode = SAI_NOCOMPANDING;
  hsai_BlockA1.Init.TriState = SAI_OUTPUT_NOTRELEASED;
  if (HAL_SAI_InitProtocol(&hsai_BlockA1, SAI_I2S_STANDARD, SAI_PROTOCOL_DATASIZE_16BIT, 2) != HAL_OK)
  {
    Error_Handler();
  }
  hsai_BlockB1.Instance = SAI1_Block_B;
  hsai_BlockB1.Init.AudioMode = SAI_MODESLAVE_RX;
  hsai_BlockB1.Init.Synchro = SAI_SYNCHRONOUS;
  hsai_BlockB1.Init.OutputDrive = SAI_OUTPUTDRIVE_DISABLE;
  hsai_BlockB1.Init.FIFOThreshold = SAI_FIFOTHRESHOLD_EMPTY;
  hsai_BlockB1.Init.SynchroExt = SAI_SYNCEXT_DISABLE;
  hsai_BlockB1.Init.MonoStereoMode = SAI_STEREOMODE;
  hsai_BlockB1.Init.CompandingMode = SAI_NOCOMPANDING;
  hsai_BlockB1.Init.TriState = SAI_OUTPUT_NOTRELEASED;
  if (HAL_SAI_InitProtocol(&hsai_BlockB1, SAI_I2S_STANDARD, SAI_PROTOCOL_DATASIZE_16BIT, 2) != HAL_OK)
  {
    Error_Handler();
  }

}

static void MX_TIM3_Init(void)
{

  TIM_ClockConfigTypeDef sClockSourceConfig = {0};
  TIM_MasterConfigTypeDef sMasterConfig = {0};

  htim3.Instance = TIM3;
  htim3.Init.Prescaler = 0;
  htim3.Init.CounterMode = TIM_COUNTERMODE_UP;
  htim3.Init.Period = 15000;
  htim3.Init.ClockDivision = TIM_CLOCKDIVISION_DIV1;
  htim3.Init.AutoReloadPreload = TIM_AUTORELOAD_PRELOAD_DISABLE;
  if (HAL_TIM_Base_Init(&htim3) != HAL_OK)
  {
    Error_Handler();
  }
  sClockSourceConfig.ClockSource = TIM_CLOCKSOURCE_INTERNAL;
  if (HAL_TIM_ConfigClockSource(&htim3, &sClockSourceConfig) != HAL_OK)
  {
    Error_Handler();
  }
  sMasterConfig.MasterOutputTrigger = TIM_TRGO_RESET;
  sMasterConfig.MasterSlaveMode = TIM_MASTERSLAVEMODE_DISABLE;
  if (HAL_TIMEx_MasterConfigSynchronization(&htim3, &sMasterConfig) != HAL_OK)
  {
    Error_Handler();
  }

}

static void MX_UART7_Init(void)
{

  huart7.Instance = UART7;
  huart7.Init.BaudRate = 115200;
  huart7.Init.WordLength = UART_WORDLENGTH_8B;
  huart7.Init.StopBits = UART_STOPBITS_1;
  huart7.Init.Parity = UART_PARITY_NONE;
  huart7.Init.Mode = UART_MODE_TX_RX;
  huart7.Init.HwFlowCtl = UART_HWCONTROL_NONE;
  huart7.Init.OverSampling = UART_OVERSAMPLING_16;
  huart7.Init.OneBitSampling = UART_ONE_BIT_SAMPLE_DISABLE;
  huart7.Init.ClockPrescaler = UART_PRESCALER_DIV1;
  huart7.AdvancedInit.AdvFeatureInit = UART_ADVFEATURE_NO_INIT;
  if (HAL_UART_Init(&huart7) != HAL_OK)
  {
    Error_Handler();
  }
  if (HAL_UARTEx_SetTxFifoThreshold(&huart7, UART_TXFIFO_THRESHOLD_1_2) != HAL_OK)
  {
    Error_Handler();
  }
  if (HAL_UARTEx_SetRxFifoThreshold(&huart7, UART_RXFIFO_THRESHOLD_1_2) != HAL_OK)
  {
    Error_Handler();
  }
  if (HAL_UARTEx_EnableFifoMode(&huart7) != HAL_OK)
  {
    Error_Handler();
  }

}

static void MX_DMA_Init(void)
{

  /* DMA controller clock enable */
  __HAL_RCC_DMA1_CLK_ENABLE();

  /* DMA interrupt init */
  /* DMA1_Stream0_IRQn interrupt configuration */
  HAL_NVIC_SetPriority(DMA1_Stream0_IRQn, 0, 0);
  HAL_NVIC_EnableIRQ(DMA1_Stream0_IRQn);
  /* DMA1_Stream1_IRQn interrupt configuration */
  HAL_NVIC_SetPriority(DMA1_Stream1_IRQn, 0, 0);
  HAL_NVIC_EnableIRQ(DMA1_Stream1_IRQn);

}

/* FMC initialization function */
static void MX_FMC_Init(void)
{

  FMC_NORSRAM_TimingTypeDef Timing = {0};

  /** Perform the SRAM1 memory initialization sequence
  */
  hsram1.Instance = FMC_NORSRAM_DEVICE;
  hsram1.Extended = FMC_NORSRAM_EXTENDED_DEVICE;
  /* hsram1.Init */
  hsram1.Init.NSBank = FMC_NORSRAM_BANK1;
  hsram1.Init.DataAddressMux = FMC_DATA_ADDRESS_MUX_DISABLE;
  hsram1.Init.MemoryType = FMC_MEMORY_TYPE_SRAM;
  hsram1.Init.MemoryDataWidth = FMC_NORSRAM_MEM_BUS_WIDTH_32;
  hsram1.Init.BurstAccessMode = FMC_BURST_ACCESS_MODE_DISABLE;
  hsram1.Init.WaitSignalPolarity = FMC_WAIT_SIGNAL_POLARITY_LOW;
  hsram1.Init.WaitSignalActive = FMC_WAIT_TIMING_BEFORE_WS;
  hsram1.Init.WriteOperation = FMC_WRITE_OPERATION_ENABLE;
  hsram1.Init.WaitSignal = FMC_WAIT_SIGNAL_DISABLE;
  hsram1.Init.ExtendedMode = FMC_EXTENDED_MODE_DISABLE;
  hsram1.Init.AsynchronousWait = FMC_ASYNCHRONOUS_WAIT_DISABLE;
  hsram1.Init.WriteBurst = FMC_WRITE_BURST_DISABLE;
  hsram1.Init.ContinuousClock = FMC_CONTINUOUS_CLOCK_SYNC_ONLY;
  hsram1.Init.WriteFifo = FMC_WRITE_FIFO_ENABLE;
  hsram1.Init.PageSize = FMC_PAGE_SIZE_NONE;
  /* Timing */
  Timing.AddressSetupTime = 15;
  Timing.AddressHoldTime = 15;
  Timing.DataSetupTime = 255;
  Timing.BusTurnAroundDuration = 15;
  Timing.CLKDivision = 16;
  Timing.DataLatency = 17;
  Timing.AccessMode = FMC_ACCESS_MODE_A;
  /* ExtTiming */

  if (HAL_SRAM_Init(&hsram1, &Timing, NULL) != HAL_OK)
  {
    Error_Handler( );
  }

}

static void MX_GPIO_Init(void)
{
  GPIO_InitTypeDef GPIO_InitStruct = {0};

  /* GPIO Ports Clock Enable */
  __HAL_RCC_GPIOE_CLK_ENABLE();
  __HAL_RCC_GPIOC_CLK_ENABLE();
  __HAL_RCC_GPIOI_CLK_ENABLE();
  __HAL_RCC_GPIOF_CLK_ENABLE();
  __HAL_RCC_GPIOH_CLK_ENABLE();
  __HAL_RCC_GPIOA_CLK_ENABLE();
  __HAL_RCC_GPIOB_CLK_ENABLE();
  __HAL_RCC_GPIOG_CLK_ENABLE();
  __HAL_RCC_GPIOD_CLK_ENABLE();

  /*Configure GPIO pin Output Level */
  HAL_GPIO_WritePin(GPIOA, UPR1_SP_Pin|MKVKL_UPR_Pin, GPIO_PIN_RESET);

  /*Configure GPIO pin Output Level */
  HAL_GPIO_WritePin(GPIOA, UPR2_FAN_Pin|RELE_UPR_Pin, GPIO_PIN_SET);

  /*Configure GPIO pin Output Level */
  HAL_GPIO_WritePin(POW_DOWN_GPIO_Port, POW_DOWN_Pin, GPIO_PIN_SET);

  /*Configure GPIO pin Output Level */
  HAL_GPIO_WritePin(NORMA_UPR_GPIO_Port, NORMA_UPR_Pin, GPIO_PIN_RESET);

  /*Configure GPIO pin Output Level */
  HAL_GPIO_WritePin(TEST_LED_GPIO_Port, TEST_LED_Pin, GPIO_PIN_RESET);

  /*Configure GPIO pins : DET_48V_Pin UPR_PHONE_Pin UPR_MIC2_Pin CFG_UI0_Pin
                           CFG_UI1_Pin CFG_UI2_Pin INT_BUT_Pin */
  GPIO_InitStruct.Pin = DET_48V_Pin|UPR_PHONE_Pin|UPR_MIC2_Pin|CFG_UI0_Pin
                          |CFG_UI1_Pin|CFG_UI2_Pin|INT_BUT_Pin;
  GPIO_InitStruct.Mode = GPIO_MODE_INPUT;
  GPIO_InitStruct.Pull = GPIO_PULLUP;
  HAL_GPIO_Init(GPIOC, &GPIO_InitStruct);

  /*Configure GPIO pins : UPR1_SP_Pin UPR2_FAN_Pin MKVKL_UPR_Pin RELE_UPR_Pin */
  GPIO_InitStruct.Pin = UPR1_SP_Pin|UPR2_FAN_Pin|MKVKL_UPR_Pin|RELE_UPR_Pin;
  GPIO_InitStruct.Mode = GPIO_MODE_OUTPUT_PP;
  GPIO_InitStruct.Pull = GPIO_PULLUP;
  GPIO_InitStruct.Speed = GPIO_SPEED_FREQ_LOW;
  HAL_GPIO_Init(GPIOA, &GPIO_InitStruct);

  /*Configure GPIO pins : POW_DOWN_Pin TEST_LED_Pin */
  GPIO_InitStruct.Pin = POW_DOWN_Pin|TEST_LED_Pin;
  GPIO_InitStruct.Mode = GPIO_MODE_OUTPUT_PP;
  GPIO_InitStruct.Pull = GPIO_PULLUP;
  GPIO_InitStruct.Speed = GPIO_SPEED_FREQ_LOW;
  HAL_GPIO_Init(GPIOB, &GPIO_InitStruct);

  /*Configure GPIO pin : PA8 */
  GPIO_InitStruct.Pin = GPIO_PIN_8;
  GPIO_InitStruct.Mode = GPIO_MODE_AF_PP;
  GPIO_InitStruct.Pull = GPIO_PULLUP;
  GPIO_InitStruct.Speed = GPIO_SPEED_FREQ_LOW;
  GPIO_InitStruct.Alternate = GPIO_AF0_MCO;
  HAL_GPIO_Init(GPIOA, &GPIO_InitStruct);

  /*Configure GPIO pins : VOL_UP_Pin VOL_DOWN_Pin SENS_UP_Pin SENS_DOWN_Pin */
  GPIO_InitStruct.Pin = VOL_UP_Pin|VOL_DOWN_Pin|SENS_UP_Pin|SENS_DOWN_Pin;
  GPIO_InitStruct.Mode = GPIO_MODE_INPUT;
  GPIO_InitStruct.Pull = GPIO_PULLUP;
  HAL_GPIO_Init(GPIOA, &GPIO_InitStruct);

  /*Configure GPIO pin : NORMA_UPR_Pin */
  GPIO_InitStruct.Pin = NORMA_UPR_Pin;
  GPIO_InitStruct.Mode = GPIO_MODE_OUTPUT_PP;
  GPIO_InitStruct.Pull = GPIO_PULLUP;
  GPIO_InitStruct.Speed = GPIO_SPEED_FREQ_LOW;
  HAL_GPIO_Init(NORMA_UPR_GPIO_Port, &GPIO_InitStruct);

  /*Configure GPIO pin : TEST_BUT_Pin */
  GPIO_InitStruct.Pin = TEST_BUT_Pin;
  GPIO_InitStruct.Mode = GPIO_MODE_INPUT;
  GPIO_InitStruct.Pull = GPIO_PULLUP;
  HAL_GPIO_Init(TEST_BUT_GPIO_Port, &GPIO_InitStruct);

}

void Error_Handler(void)
{
  __disable_irq();
  while (1)
  {
  }
}
